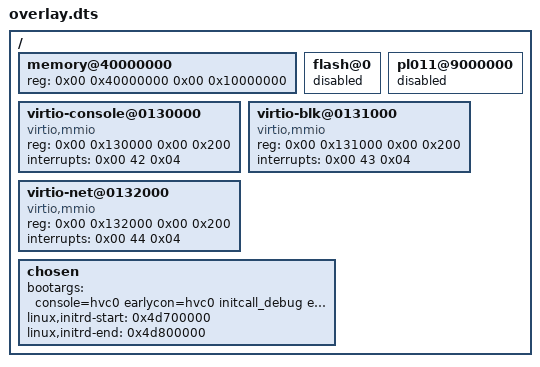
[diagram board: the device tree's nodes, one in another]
/*
 * Copyright 2024, UNSW
 *
 * SPDX-License-Identifier: BSD-2-Clause
 */
/ {
    /* Need to specify how much RAM the guest will have */
    memory@40000000 {
        device_type = "memory";
        reg = <0x00 0x40000000 0x00 0x10000000>;
    };

    flash@0 {
        status = "disabled";
    };

    pl011@9000000 {
        status = "disabled";
    };

    virtio-console@0130000 {
        compatible = "virtio,mmio";
        reg = <0x00 0x130000 0x00 0x200>;
        interrupts = <0x00 42 0x04>;
    };

    virtio-blk@0131000 {
        compatible = "virtio,mmio";
        reg = <0x00 0x131000 0x00 0x200>;
        interrupts = <0x00 43 0x04>;
    };

    virtio-net@0132000 {
        compatible = "virtio,mmio";
        reg = <0x00 0x132000 0x00 0x200>;
        interrupts = <0x00 44 0x04>;
    };

    chosen {
        bootargs = "console=hvc0 earlycon=hvc0 initcall_debug earlyprintk=serial debug loglevel=8";
        linux,initrd-start = <0x4d700000>;
        linux,initrd-end = <0x4d800000>;
    };
};
